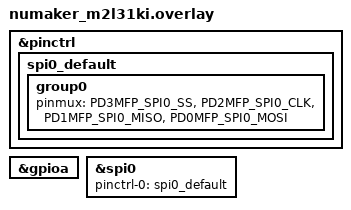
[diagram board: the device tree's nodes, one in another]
/* SPDX-FileCopyrightText: Copyright The Zephyr Project Contributors */
/* SPDX-License-Identifier: Apache-2.0 */

&pinctrl {
	/* EVB's NU5: SS/CLK/MISO/MOSI */
	spi0_default: spi0_default {
		group0 {
			pinmux = <PD3MFP_SPI0_SS>,
				 <PD2MFP_SPI0_CLK>,
				 <PD1MFP_SPI0_MISO>,
				 <PD0MFP_SPI0_MOSI>;
		};
	};
};

&gpioa {
	status = "okay";
};

spi_loopback: &spi0 {
	status = "okay";
	pinctrl-0 = <&spi0_default>;
	pinctrl-names = "default";
};

#include "../spi-loopback.dtsi"
